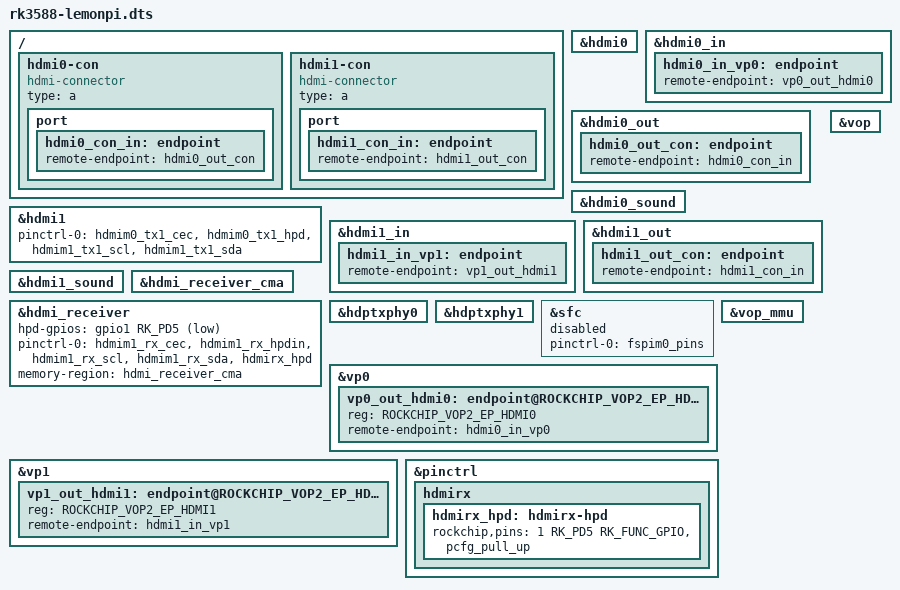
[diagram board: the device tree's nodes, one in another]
// SPDX-License-Identifier: (GPL-2.0+ OR MIT)
/*
 * Copyright (c) 2021 Rockchip Electronics Co., Ltd.
 * 
 * Device Tree Source for LemonPi board on Rockchip RK3588 SoC.
 * Kernel Version Target: 6.14
 */

/dts-v1/;
#include "rk3588-lemonpi.dtsi"

/ {
	hdmi0-con {
		compatible = "hdmi-connector";
		type = "a";

		port {
			hdmi0_con_in: endpoint {
				remote-endpoint = <&hdmi0_out_con>;
			};
		};
	};

	hdmi1-con {
		compatible = "hdmi-connector";
		type = "a";

		port {
			hdmi1_con_in: endpoint {
				remote-endpoint = <&hdmi1_out_con>;
			};
		};
	};
};

&hdmi0 {
	status = "okay";
};

&hdmi0_in {
	hdmi0_in_vp0: endpoint {
		remote-endpoint = <&vp0_out_hdmi0>;
	};
};

&hdmi0_out {
	hdmi0_out_con: endpoint {
		remote-endpoint = <&hdmi0_con_in>;
	};
};

&hdmi0_sound {
	status = "okay";
};

&hdmi1 {
	pinctrl-0 = <&hdmim0_tx1_cec &hdmim0_tx1_hpd
		     &hdmim1_tx1_scl &hdmim1_tx1_sda>;
	status = "okay";
};

&hdmi1_in {
	hdmi1_in_vp1: endpoint {
		remote-endpoint = <&vp1_out_hdmi1>;
	};
};

&hdmi1_out {
	hdmi1_out_con: endpoint {
		remote-endpoint = <&hdmi1_con_in>;
	};
};

&hdmi1_sound {
	status = "okay";
};

&hdmi_receiver_cma {
	status = "okay";
};

&hdmi_receiver {
	status = "okay";
	hpd-gpios = <&gpio1 RK_PD5 GPIO_ACTIVE_LOW>;
	pinctrl-0 = <&hdmim1_rx_cec &hdmim1_rx_hpdin &hdmim1_rx_scl &hdmim1_rx_sda &hdmirx_hpd>;
	pinctrl-names = "default";
	memory-region = <&hdmi_receiver_cma>;
};

&hdptxphy0 {
	status = "okay";
};

&hdptxphy1 {
	status = "okay";
};

&sfc {
	status = "disabled";
	pinctrl-names = "default";
	pinctrl-0 = <&fspim0_pins>;
};

&vop_mmu {
	status = "okay";
};

&vop {
	status = "okay";
};

&vp0 {
	vp0_out_hdmi0: endpoint@ROCKCHIP_VOP2_EP_HDMI0 {
		reg = <ROCKCHIP_VOP2_EP_HDMI0>;
		remote-endpoint = <&hdmi0_in_vp0>;
	};
};

&vp1 {
	vp1_out_hdmi1: endpoint@ROCKCHIP_VOP2_EP_HDMI1 {
		reg = <ROCKCHIP_VOP2_EP_HDMI1>;
		remote-endpoint = <&hdmi1_in_vp1>;
	};
};


&pinctrl {
	hdmirx {
		hdmirx_hpd: hdmirx-hpd {
			rockchip,pins = <1 RK_PD5 RK_FUNC_GPIO &pcfg_pull_up>;
		};
	};
};
